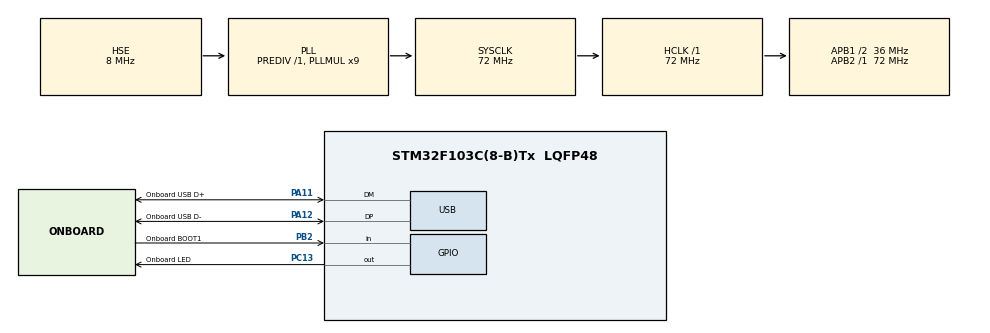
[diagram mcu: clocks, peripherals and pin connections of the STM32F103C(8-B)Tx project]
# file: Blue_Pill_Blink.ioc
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Mcu.Family=STM32F1
Mcu.Name=STM32F103C(8-B)Tx
Mcu.Package=LQFP48
NVIC.PriorityGroup=NVIC_PRIORITYGROUP_4
NVIC.USB_LP_CAN1_RX0_IRQn=true\:0\:0\:false\:false\:true\:false
PA11.GPIO_Label=Onboard USB D+
PA11.Mode=Device
PA11.Signal=USB_DM
PA12.GPIO_Label=Onboard USB D-
PA12.Mode=Device
PA12.Signal=USB_DP
PA13.GPIO_Label=Onboard SWDIO
PA13.Mode=Serial_Wire
PA13.Signal=SYS_JTMS-SWDIO
PA14.GPIO_Label=Onboard SWCLK
PA14.Mode=Serial_Wire
PA14.Signal=SYS_JTCK-SWCLK
PB2.GPIO_Label=Onboard BOOT1
PB2.Signal=GPIO_Input
PC13-TAMPER-RTC.GPIO_Label=Onboard LED
PC13-TAMPER-RTC.Signal=GPIO_Output
PC14-OSC32_IN.GPIO_Label=Onboard 32K XTAL1
PC14-OSC32_IN.Mode=LSE-External-Oscillator
PC14-OSC32_IN.Signal=RCC_OSC32_IN
PC15-OSC32_OUT.GPIO_Label=Onboard 32K XTAL2
PC15-OSC32_OUT.Mode=LSE-External-Oscillator
PC15-OSC32_OUT.Signal=RCC_OSC32_OUT
PD0-OSC_IN.GPIO_Label=Onboard 8M XTAL1
PD0-OSC_IN.Mode=HSE-External-Oscillator
PD0-OSC_IN.Signal=RCC_OSC_IN
PD1-OSC_OUT.GPIO_Label=Onboard 8M XTAL2
PD1-OSC_OUT.Mode=HSE-External-Oscillator
PD1-OSC_OUT.Signal=RCC_OSC_OUT
ProjectManager.HeapSize=0x200
ProjectManager.StackSize=0x400
ProjectManager.TargetToolchain=TrueSTUDIO
RCC.AHBFreq_Value=72000000
RCC.APB1CLKDivider=RCC_HCLK_DIV2
RCC.APB1Freq_Value=36000000
RCC.APB1TimFreq_Value=72000000
RCC.APB2Freq_Value=72000000
RCC.APB2TimFreq_Value=72000000
RCC.HCLKFreq_Value=72000000
RCC.PLLMUL=RCC_PLL_MUL9
RCC.SYSCLKFreq_VALUE=72000000
RCC.SYSCLKSource=RCC_SYSCLKSOURCE_PLLCLK
RCC.USBFreq_Value=48000000
RCC.USBPrescaler=RCC_USBCLKSOURCE_PLL_DIV1_5
USB_DEVICE.CLASS_NAME_FS=CDC
USB_DEVICE.VirtualMode=Cdc
USB_DEVICE.VirtualModeFS=Cdc_FS
VP_USB_DEVICE_VS_USB_DEVICE_CDC_FS.Mode=CDC_FS
board=Blue_Pill_Blink

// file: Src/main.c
/**
  ******************************************************************************
  * File Name          : main.c
  * Description        : Main program body
  ******************************************************************************
  * This notice applies to any and all portions of this file
  * that are not between comment pairs USER CODE BEGIN and
  * USER CODE END. Other portions of this file, whether
  * inserted by the user or by software development tools
  * are owned by their respective copyright owners.
  *
  * Copyright (c) 2018 STMicroelectronics International N.V.
  * All rights reserved.
  *
  * Redistribution and use in source and binary forms, with or without
  * modification, are permitted, provided that the following conditions are met:
  *
  * 1. Redistribution of source code must retain the above copyright notice,
  *    this list of conditions and the following disclaimer.
  * 2. Redistributions in binary form must reproduce the above copyright notice,
  *    this list of conditions and the following disclaimer in the documentation
  *    and/or other materials provided with the distribution.
  * 3. Neither the name of STMicroelectronics nor the names of other
  *    contributors to this software may be used to endorse or promote products
  *    derived from this software without specific written permission.
  * 4. This software, including modifications and/or derivative works of this
  *    software, must execute solely and exclusively on microcontroller or
  *    microprocessor devices manufactured by or for STMicroelectronics.
  * 5. Redistribution and use of this software other than as permitted under
  *    this license is void and will automatically terminate your rights under
  *    this license.
  *
  * THIS SOFTWARE IS PROVIDED BY STMICROELECTRONICS AND CONTRIBUTORS "AS IS"
  * AND ANY EXPRESS, IMPLIED OR STATUTORY WARRANTIES, INCLUDING, BUT NOT
  * LIMITED TO, THE IMPLIED WARRANTIES OF MERCHANTABILITY, FITNESS FOR A
  * PARTICULAR PURPOSE AND NON-INFRINGEMENT OF THIRD PARTY INTELLECTUAL PROPERTY
  * RIGHTS ARE DISCLAIMED TO THE FULLEST EXTENT PERMITTED BY LAW. IN NO EVENT
  * SHALL STMICROELECTRONICS OR CONTRIBUTORS BE LIABLE FOR ANY DIRECT, INDIRECT,
  * INCIDENTAL, SPECIAL, EXEMPLARY, OR CONSEQUENTIAL DAMAGES (INCLUDING, BUT NOT
  * LIMITED TO, PROCUREMENT OF SUBSTITUTE GOODS OR SERVICES; LOSS OF USE, DATA,
  * OR PROFITS; OR BUSINESS INTERRUPTION) HOWEVER CAUSED AND ON ANY THEORY OF
  * LIABILITY, WHETHER IN CONTRACT, STRICT LIABILITY, OR TORT (INCLUDING
  * NEGLIGENCE OR OTHERWISE) ARISING IN ANY WAY OUT OF THE USE OF THIS SOFTWARE,
  * EVEN IF ADVISED OF THE POSSIBILITY OF SUCH DAMAGE.
  *
  ******************************************************************************
  */

#include "main.h"
#include "stm32f1xx_hal.h"
#include "usb_device.h"
#include "gpio.h"

/* USER CODE BEGIN PV */
/* Private variables ---------------------------------------------------------*/
//
//  Let's define a simple message to send out of the USB Virtual COMM Port
//
uint8_t Msg[] = "LED Blink\n\r";
/* USER CODE END PV */

void SystemClock_Config(void);

/* USER CODE BEGIN PFP */
/* Private function prototypes -----------------------------------------------*/

/* USER CODE END PFP */

int main(void)
{

  /* MCU Configuration----------------------------------------------------------*/

  /* Reset of all peripherals, Initializes the Flash interface and the Systick. */
  HAL_Init();

  /* Configure the system clock */
  SystemClock_Config();

  /* Initialize all configured peripherals */
  MX_GPIO_Init();
  MX_USB_DEVICE_Init();

  /* Infinite loop */
  while (1)
  {

  /* USER CODE BEGIN 3 */

  // Be sure to place your code in-between the BEGIN/END comments to preserve it
  // through code re-generation

  // Look at gpio.c around line 84 - the LED pin carries over the name defined in
  //STM32CubeMX so the simplest method of blinking the LED is to use the HAL_GPIO_Toggle
  // function which requires the port and pin as arguments
  HAL_GPIO_TogglePin(Onboard_LED_GPIO_Port, Onboard_LED_Pin) ;
  // You could alternatively use the following line and comment out the above line
  // and it is the same
  // HAL_GPIO_Toggle(GPIOC, GPIO_PIN_13);
  // You could also use separate commands to turn the line on and off using the
  // HAL_GPIO_WritePin() Function as follows. It requires the port, pin and state as
  // arguments
  // HAL_GPIO_WritePin(Onboard_LED_GPIO_Port, Onboard_LED_Pin, 0);  // Turn LED On
  HAL_Delay(500); // wait 500mS
  // HAL_GPIO_WritePin(Onboard_LED_GPIO_Port, Onboard_LED_Pin, 1);  // Turn LED Off
  // add another delay is using separate write commands
  // HAL_Delay(500);  // wait another 500mS if using separate write commands
  //
  // Now let's send a message out over the USB Virtual Comm Port each time we loop
  CDC_Transmit_FS(Msg, strlen(Msg));

  }
  /* USER CODE END 3 */

}

/** System Clock Configuration
*/
void SystemClock_Config(void)
{

  RCC_OscInitTypeDef RCC_OscInitStruct;
  RCC_ClkInitTypeDef RCC_ClkInitStruct;
  RCC_PeriphCLKInitTypeDef PeriphClkInit;

    /**Initializes the CPU, AHB and APB busses clocks
    */
  RCC_OscInitStruct.OscillatorType = RCC_OSCILLATORTYPE_HSE;
  RCC_OscInitStruct.HSEState = RCC_HSE_ON;
  RCC_OscInitStruct.HSEPredivValue = RCC_HSE_PREDIV_DIV1;
  RCC_OscInitStruct.HSIState = RCC_HSI_ON;
  RCC_OscInitStruct.PLL.PLLState = RCC_PLL_ON;
  RCC_OscInitStruct.PLL.PLLSource = RCC_PLLSOURCE_HSE;
  RCC_OscInitStruct.PLL.PLLMUL = RCC_PLL_MUL9;
  if (HAL_RCC_OscConfig(&RCC_OscInitStruct) != HAL_OK)
  {
    _Error_Handler(__FILE__, __LINE__);
  }

    /**Initializes the CPU, AHB and APB busses clocks
    */
  RCC_ClkInitStruct.ClockType = RCC_CLOCKTYPE_HCLK|RCC_CLOCKTYPE_SYSCLK
                              |RCC_CLOCKTYPE_PCLK1|RCC_CLOCKTYPE_PCLK2;
  RCC_ClkInitStruct.SYSCLKSource = RCC_SYSCLKSOURCE_PLLCLK;
  RCC_ClkInitStruct.AHBCLKDivider = RCC_SYSCLK_DIV1;
  RCC_ClkInitStruct.APB1CLKDivider = RCC_HCLK_DIV2;
  RCC_ClkInitStruct.APB2CLKDivider = RCC_HCLK_DIV1;

  if (HAL_RCC_ClockConfig(&RCC_ClkInitStruct, FLASH_LATENCY_2) != HAL_OK)
  {
    _Error_Handler(__FILE__, __LINE__);
  }

  PeriphClkInit.PeriphClockSelection = RCC_PERIPHCLK_USB;
  PeriphClkInit.UsbClockSelection = RCC_USBCLKSOURCE_PLL_DIV1_5;
  if (HAL_RCCEx_PeriphCLKConfig(&PeriphClkInit) != HAL_OK)
  {
    _Error_Handler(__FILE__, __LINE__);
  }

    /**Configure the Systick interrupt time
    */
  HAL_SYSTICK_Config(HAL_RCC_GetHCLKFreq()/1000);

    /**Configure the Systick
    */
  HAL_SYSTICK_CLKSourceConfig(SYSTICK_CLKSOURCE_HCLK);

  /* SysTick_IRQn interrupt configuration */
  HAL_NVIC_SetPriority(SysTick_IRQn, 0, 0);
}

void _Error_Handler(char * file, int line)
{
  while(1)
  {
  }
}

/************************ (C) COPYRIGHT STMicroelectronics *****END OF FILE****/
